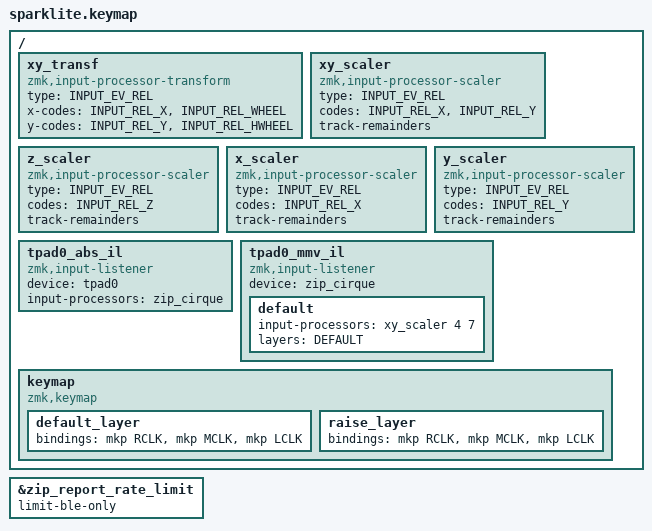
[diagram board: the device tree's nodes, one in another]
/*
 * Copyright (c) 2020 The ZMK Contributors
 *
 * SPDX-License-Identifier: MIT
 */

#include <zephyr/dt-bindings/input/input-event-codes.h>

#include <behaviors.dtsi>
// #include <behaviors/mouse_keys.dtsi>
#include <behaviors/mouse_key_press.dtsi>
#include <behaviors/mouse_key_toggle.dtsi>
#include <dt-bindings/zmk/keys.h>
#include <dt-bindings/zmk/bt.h>
#include <dt-bindings/zmk/rgb.h>
#include <dt-bindings/zmk/ext_power.h>
#include <dt-bindings/zmk/outputs.h>
#include <dt-bindings/zmk/mouse.h>
#include <dt-bindings/zmk/input_transform.h>
#include <input/processors.dtsi>

#include <input/processors/cirque.dtsi>
#include <dt-bindings/zmk/zip_cirque_attr.h>

#include <input/processors/mixer.dtsi>
#include <input/processors/trixer.dtsi>
#include <input/processors/quadixer.dtsi>
#include <input/processors/report_rate_limit.dtsi>

#define DEFAULT 0
#define RAISE   1

// #define OUTPUT_SOURCE_LAYER_STATE_CHANGE        1
// #define OUTPUT_SOURCE_POSITION_STATE_CHANGE     2
// #define OUTPUT_SOURCE_KEYCODE_STATE_CHANGE      3
// #define OUTPUT_SOURCE_TRANSPORT                 4

&zip_report_rate_limit {
        limit-ble-only;
};

/ {
        xy_transf: xy_transf {
                compatible = "zmk,input-processor-transform";
                #input-processor-cells = <1>;
                type = <INPUT_EV_REL>;
                x-codes = <INPUT_REL_X>, <INPUT_REL_WHEEL>;
                y-codes = <INPUT_REL_Y>, <INPUT_REL_HWHEEL>;
        };
        xy_scaler: xy_scaler {
                compatible = "zmk,input-processor-scaler";
                #input-processor-cells = <2>;
                type = <INPUT_EV_REL>;
                codes = <INPUT_REL_X>, <INPUT_REL_Y>;
                track-remainders;
        };
        z_scaler: z_scaler {
                compatible = "zmk,input-processor-scaler";
                #input-processor-cells = <2>;
                type = <INPUT_EV_REL>;
                codes = <INPUT_REL_Z>;
                track-remainders;
        };
        x_scaler: x_scaler {
                compatible = "zmk,input-processor-scaler";
                #input-processor-cells = <2>;
                type = <INPUT_EV_REL>;
                codes = <INPUT_REL_X>;
                track-remainders;
        };
        y_scaler: y_scaler {
                compatible = "zmk,input-processor-scaler";
                #input-processor-cells = <2>;
                type = <INPUT_EV_REL>;
                codes = <INPUT_REL_Y>;
                track-remainders;
        };

        // mlxpuck1_il {
        //         compatible = "zmk,input-listener";
        //         device = <&mlxpuck1>;
        //         input-processors = <&xy_transf (INPUT_TRANSFORM_Y_INVERT)>
        //                         ,  <&xy_scaler 1 30>, <&z_scaler 1 30>
        //                         ,  <&zip_trixer 0>;
        // };
        // mlxpuck2_il {
        //         compatible = "zmk,input-listener";
        //         device = <&mlxpuck2>;
        //         input-processors = <&xy_transf (INPUT_TRANSFORM_Y_INVERT)>
        //                         ,  <&xy_scaler 1 30>, <&z_scaler 1 30>
        //                         ,  <&zip_trixer 1>;
        // };
        // mlxpuck3_il {
        //         compatible = "zmk,input-listener";
        //         device = <&mlxpuck3>;
        //         input-processors = <&xy_transf (INPUT_TRANSFORM_Y_INVERT)>
        //                         ,  <&xy_scaler 1 30>, <&z_scaler 1 30>
        //                         ,  <&zip_trixer 2>;
        // };
        // trixer_il {
	// 	compatible = "zmk,input-listener";
	// 	device = <&zip_trixer>;
        //         input-processors = <&zip_fwd_to_hid_joystick>;
        //         // input-processors = <&xy_scaler 3 7>, <&z_scaler 3 7>;
	// };

        // patpuck1_il {
        //         compatible = "zmk,input-listener";
        //         device = <&patpuck1>;
        //         input-processors = <&zip_quadixer 0>;
        // };
        // patpuck2_il {
        //         compatible = "zmk,input-listener";
        //         device = <&patpuck2>;
        //         input-processors = <&zip_quadixer 1>;
        // };
        // patpuck3_il {
        //         compatible = "zmk,input-listener";
        //         device = <&patpuck3>;
        //         input-processors = <&zip_quadixer 2>;
        // };
        // patpuck4_il {
        //         compatible = "zmk,input-listener";
        //         device = <&patpuck4>;
        //         input-processors = <&zip_quadixer 3>;
        // };
        // quadixer_il {
	// 	compatible = "zmk,input-listener";
	// 	device = <&zip_quadixer>;
        //         input-processors = <&zip_fwd_to_hid_joystick>;
	// };


        // zip_fwd_to_hid_joystick: zip_forward_fwd_to_hid_joystick {
        //         compatible = "zmk,input-processor-fwd-to-hid-joystick";
        //         #input-processor-cells = <0>;
        // };
        // jskp: hid_joystick_key_press {
        //         compatible = "zmk,behavior-hid-joystick-key-press";
        //         #binding-cells = <1>;
        // };
	// jskp_il {
	// 	compatible = "zmk,input-listener";
	// 	device = <&jskp>;
        //         input-processors = <&zip_fwd_to_hid_joystick>;
	// };


        // tball1_pri_mmv_il {
        //         compatible = "zmk,input-listener";
        //         device = <&pd0>;
        //         default {
        //                 layers = <DEFAULT>;
        //                 // sensor at 6 o'clock pos
        //                 input-processors = <&zip_xy_swap_mapper>
        //                                  , <&zip_xy_transform (INPUT_TRANSFORM_Y_INVERT)>
        //                                  , <&zip_mixer 0>;
        //         };
        // };
        // tball1_sec_mmv_il {
        //         compatible = "zmk,input-listener";
        //         device = <&pd0a>;
        //         default {
        //                 layers = <DEFAULT>;
        //                 // sensor at 3 o'clock pos
        //                 input-processors = <&zip_mixer 1>;
        //         };
        // };
        // mixin_mmv_il {
        //         compatible = "zmk,input-listener";
        //         device = <&zip_mixer>;
        //         input-processors = <&zip_report_rate_limit 12>;
        // };

        // tball1_mmv_il {
        //         compatible = "zmk,input-listener";
        //         device = <&pd0>;
        //         default {
        //                 layers = <DEFAULT>;
        //                 // input-processors = <&zip_xy_transform (INPUT_TRANSFORM_X_INVERT)>;
        //                 // input-processors 
        //                 //         = <&zip_xy_swap_mapper>
        //                 //         , <&zip_xy_transform (INPUT_TRANSFORM_X_INVERT)>
        //                 //         ;
        //         };
        // };

        // tball2_mmv_il {
        //         compatible = "zmk,input-listener";
        //         device = <&pd0i>;
        //         default {
        //                 layers = <DEFAULT>;
        //         };
        // };

        tpad0_abs_il: tpad0_abs_il {
                compatible = "zmk,input-listener";
                device = <&tpad0>;
                input-processors = <&zip_cirque>;
        };
        tpad0_mmv_il {
                compatible = "zmk,input-listener";
                device = <&zip_cirque>;
                default {
                        // input-processors = <&xy_transf (INPUT_TRANSFORM_Y_INVERT)>
                        //                  , <&x_scaler 4 3>, <&y_scaler 5 3>;
                        input-processors = <&xy_scaler 4 7>;
                        layers = <DEFAULT>;
                };
        };
        // behaviors {
        //         cirque_inertial: cirque_inertial {
        //                 compatible = "zmk,behavior-sensor-attr-cycle";
        //                 #binding-cells = <1>;
        //                 sensor_device = <&zip_cirque_setter>;
        //                 attr = <ZIP_CIRQUE_ATTR_INERTIAL_ENABLE>;
        //                 values = <1 0>;
        //         };
        //         cirque_scroll_trigger_haptic: cirque_scroll_trigger_haptic {
        //                 compatible = "zmk,behavior-sensor-attr-cycle";
        //                 #binding-cells = <1>;
        //                 sensor_device = <&zip_cirque_setter>;
        //                 attr = <ZIP_CIRQUE_ATTR_FEEDBACK_EDGE_SCROLL_TRIGGER_ENABLE>;
        //                 values = <1 0>;
        //         };
        //         cirque_inertial_decay: cirque_inertial_decay {
        //                 compatible = "zmk,behavior-sensor-attr-cycle";
        //                 #binding-cells = <1>;
        //                 sensor_device = <&zip_cirque_setter>;
        //                 attr = <ZIP_CIRQUE_ATTR_INERTIAL_DECAY_PCT>;
        //                 values = <100 97 93 90 85 80>;
        //         };
        // };

        // erm0_obl__enter_raise_layer {
        //         compatible = "zmk,output-behavior-listener";
        //         layers = < RAISE >;
        //         sources = < OUTPUT_SOURCE_LAYER_STATE_CHANGE >;
        //         bindings = < &ob_erm0_in &ob_erm0_out >;
        // };
        // erm0_obl__back_to_default_layer {
        //         compatible = "zmk,output-behavior-listener";
        //         layers = < DEFAULT >;
        //         sources = < OUTPUT_SOURCE_LAYER_STATE_CHANGE >;
        //         invert-state;
        //         bindings = < &ob_erm0_out >;
        // };
        // erm0_obl__press_position_5 {
        //         compatible = "zmk,output-behavior-listener";
        //         layers = < DEFAULT >;
        //         sources = < OUTPUT_SOURCE_POSITION_STATE_CHANGE >;
        //         position = <5>;
        //         bindings = < &ob_erm0_in >;
        // };
        // erm0_obl__press_key_code_D {
        //         compatible = "zmk,output-behavior-listener";
        //         layers = < DEFAULT >;
        //         sources = < OUTPUT_SOURCE_KEYCODE_STATE_CHANGE >;
        //         position = < 0x07 >;
        //         bindings = < &ob_erm0_in >;
        // };
        // ob_erm0_in: ob_generic_erm0_in {
        //         compatible = "zmk,output-behavior-generic"; #binding-cells = <0>;
        //         device = <&lra0>; delay = <1>; time-to-live-ms = <30>; force = <80>;
        // };
        // ob_erm0_out: ob_generic_erm0_out {
        //         compatible = "zmk,output-behavior-generic"; #binding-cells = <0>;
        //         device = <&lra0>; delay = <133>; time-to-live-ms = <10>; force = <30>;
        // };

        keymap {
                compatible = "zmk,keymap";
                default_layer {
                        bindings = <

// &cirque_inertial 1  &cirque_scroll_trigger_haptic 1  &cirque_inertial_decay 1
&mkp RCLK   &mkp MCLK   &mkp LCLK
// &jskp 0
// &trans

//    &bt BT_CLR   &out OUT_TOG      &mkp LCLK   &mkp RCLK
//    &mkp LCLK    &mo RAISE         &mkp MCLK   &mktg MB4
//    &mkp MCLK   &mkp RCLK   &mkp LCLK
                                >;
                };
                raise_layer {
                        bindings = <

// &cirque_inertial 1  &cirque_scroll_trigger_haptic 1  &cirque_inertial_decay 1
&mkp RCLK   &mkp MCLK   &mkp LCLK
// &jskp 0
// &trans

//    &trans       &trans            &trans       &trans
//    &trans       &trans            &trans       &trans
//    &trans       &trans       &trans
                                >;
                };
       };
};
